AUTOSAR XML (schema 4-2-2)
package /STELLANTIS/EPT/ASWCs
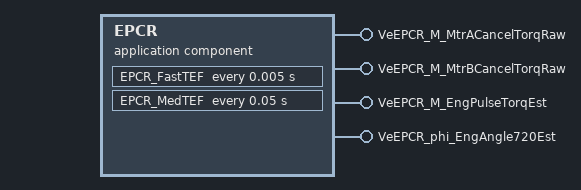
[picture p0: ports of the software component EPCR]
  application sw component type EPCR
    4 x provide port, all with nonqueued-sender-com-spec{data-element=Value, init-value=0}:
      VeEPCR_M_MtrACancelTorqRaw: provided-interface=VeEPCR_M_MtrACancelTorqRaw
      VeEPCR_M_MtrBCancelTorqRaw: provided-interface=VeEPCR_M_MtrBCancelTorqRaw
      VeEPCR_M_EngPulseTorqEst: provided-interface=VeEPCR_M_EngPulseTorqEst
      VeEPCR_phi_EngAngle720Est: provided-interface=VeEPCR_phi_EngAngle720Est
    behavior IB_EPCR: data-type-mapping=msADTtoIDTMapping, handle-termination-and-restart=NO-SUPPORT, included-data-type-set=data-type=TeEPCR_e_EngineAngleSourceSelector
      timing event Event_FastTEF: start-on-event=EPCR_FastTEF, period=0.005
      timing event Event_MedTEF: start-on-event=EPCR_MedTEF, period=0.05
      init event Event_EPCR_ac_Init: start-on-event=EPCR_ac_Init
      init event Event_PwrOn: start-on-event=EPCR_PwrOn
      explicit-inter-runnable-variables:
        10 x data, all with sw-calibration-access=READ-ONLY:
          Enable_write_IRV: category=VALUE, type=Boolean, init-value=0
          VaEPCR_p_InitialCylPrs_write_IRV: category=ARRAY, type=rt_Array_Float_8, init-value=8 x 0
          VaEPCR_V_InitialCylVol_write_IRV: category=ARRAY, type=rt_Array_Float_8, init-value=8 x 0
          VaEPCR_phi_IntVlvCls_write_IRV: category=ARRAY, type=rt_Array_Float_8, init-value=8 x 0
          VaEPCR_phi_IntVlvOpen_write_IRV: category=ARRAY, type=rt_Array_Float_8, init-value=8 x 0
          VaEPCR_p_CylPres_write_IRV: category=ARRAY, type=rt_Array_Float_8, init-value=8 x 0
          InitActive_write_IRV: category=VALUE, type=Boolean, init-value=0
          VaEPCR_e_ValveState_write_IRV: category=ARRAY, type=rt_Array_TeEPCR_e_ValveSt_8, init-value=8 x CeEPCR_e_ValvesClosed
          VaEPCR_e_LifterState_write_IRV: category=ARRAY, type=rt_Array_TeEPCR_e_LifterSt_8, init-value=8 x CeEPCR_e_LifterLeaking
          VeEPCR_phi_DamperTwistEst_write_IRV: category=VALUE, type=Float, init-value=0
      4 x runnable:
        EPCR_ac_Init
        EPCR_PwrOn
          data-send-points:
            4 x access:
              OUT_VeEPCR_M_MtrACancelTorqRaw_Value: accessed-variable=VeEPCR_M_MtrACancelTorqRaw.Value
              OUT_VeEPCR_M_MtrBCancelTorqRaw_Value: accessed-variable=VeEPCR_M_MtrBCancelTorqRaw.Value
              OUT_VeEPCR_M_EngPulseTorqEst_Value: accessed-variable=VeEPCR_M_EngPulseTorqEst.Value
              OUT_VeEPCR_phi_EngAngle720Est_Value: accessed-variable=VeEPCR_phi_EngAngle720Est.Value
          written-local-variables:
            10 x access:
              WV_Enable_write_IRV: accessed-variable=Enable_write_IRV
              WV_InitActive_write_IRV: accessed-variable=InitActive_write_IRV
              WV_VaEPCR_V_InitialCylVol_write_IRV: accessed-variable=VaEPCR_V_InitialCylVol_write_IRV
              WV_VaEPCR_e_LifterState_write_IRV: accessed-variable=VaEPCR_e_LifterState_write_IRV
              WV_VaEPCR_e_ValveState_write_IRV: accessed-variable=VaEPCR_e_ValveState_write_IRV
              WV_VaEPCR_p_CylPres_write_IRV: accessed-variable=VaEPCR_p_CylPres_write_IRV
              WV_VaEPCR_p_InitialCylPrs_write_IRV: accessed-variable=VaEPCR_p_InitialCylPrs_write_IRV
              WV_VaEPCR_phi_IntVlvCls_write_IRV: accessed-variable=VaEPCR_phi_IntVlvCls_write_IRV
              WV_VaEPCR_phi_IntVlvOpen_write_IRV: accessed-variable=VaEPCR_phi_IntVlvOpen_write_IRV
              WV_VeEPCR_phi_DamperTwistEst_write_IRV: accessed-variable=VeEPCR_phi_DamperTwistEst_write_IRV
        EPCR_FastTEF
          data-send-points:
            4 x access:
              OUT_VeEPCR_phi_EngAngle720Est_Value: accessed-variable=VeEPCR_phi_EngAngle720Est.Value
              OUT_VeEPCR_M_EngPulseTorqEst_Value: accessed-variable=VeEPCR_M_EngPulseTorqEst.Value
              OUT_VeEPCR_M_MtrACancelTorqRaw_Value: accessed-variable=VeEPCR_M_MtrACancelTorqRaw.Value
              OUT_VeEPCR_M_MtrBCancelTorqRaw_Value: accessed-variable=VeEPCR_M_MtrBCancelTorqRaw.Value
          written-local-variables:
            4 x access:
              WV_VaEPCR_e_LifterState_write_IRV: accessed-variable=VaEPCR_e_LifterState_write_IRV
              WV_VaEPCR_e_ValveState_write_IRV: accessed-variable=VaEPCR_e_ValveState_write_IRV
              WV_VaEPCR_p_CylPres_write_IRV: accessed-variable=VaEPCR_p_CylPres_write_IRV
              WV_VeEPCR_phi_DamperTwistEst_write_IRV: accessed-variable=VeEPCR_phi_DamperTwistEst_write_IRV
        EPCR_MedTEF
      4 x variation point proxy, all with category=CONDITION, condition-access=0:
        Variant_EPCR_DamperTwistEst
        Variant_EPCR_DampertTwistValid
        Variant_EPCR_FuncEnable
        Variant_EPCR_LeadCompEngAngleEst
